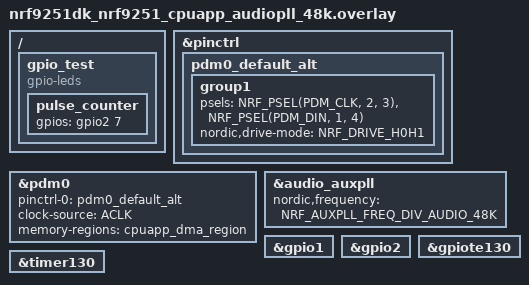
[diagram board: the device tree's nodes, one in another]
/*
 * Copyright (c) 2026 Nordic Semiconductor ASA
 *
 * SPDX-License-Identifier: LicenseRef-Nordic-5-Clause
 */

/* Test requires loopback between P2.03 and P2.07.
 * For best performance, PDM_CLK shall be on 'Clock pin'.
 */

/ {
	gpio_test {
		compatible = "gpio-leds";

		pulse_counter: pulse_counter {
			gpios = <&gpio2 7 GPIO_ACTIVE_HIGH>;
		};
	};
};

&pinctrl {
	pdm0_default_alt: pdm0_default_alt {
		group1 {
			psels = <NRF_PSEL(PDM_CLK, 2, 3)>,
				<NRF_PSEL(PDM_DIN, 1, 4)>;
			nordic,drive-mode = <NRF_DRIVE_H0H1>;
		};
	};
};

pdm_dev: &pdm0 {
	status = "okay";
	pinctrl-0 = <&pdm0_default_alt>;
	pinctrl-names = "default";
	clock-source = "ACLK";
	memory-regions = <&cpuapp_dma_region>;
};

&audio_auxpll {
	status = "okay";
	nordic,frequency = <NRF_AUXPLL_FREQ_DIV_AUDIO_48K>;
};

&gpio1 {
	status = "okay";
};

&gpio2 {
	status = "okay";
};

&gpiote130 {
	status = "okay";
};

&timer130 {
	status = "okay";
};
